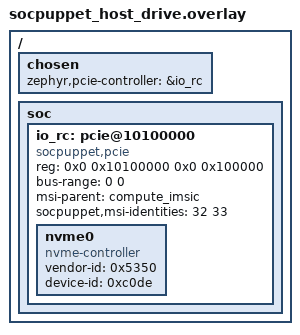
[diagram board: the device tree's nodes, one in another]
/ {
	chosen {
		zephyr,pcie-controller = &io_rc;
	};

	soc {
		io_rc: pcie@10100000 {
			compatible = "socpuppet,pcie";
			reg = <0x0 0x10100000 0x0 0x100000>;
			device_type = "pci";
			#address-cells = <3>;
			#size-cells = <2>;
			bus-range = <0 0>;
			ranges = <0x2000000 0x0 0x10800000 0x0 0x10800000 0x0 0x100000>;
		};
	};
};

&io_rc {
	msi-parent = <&compute_imsic>;
	socpuppet,msi-identities = <32 33>;

	nvme0: nvme0 {
		compatible = "nvme-controller";
		vendor-id = <0x5350>;
		device-id = <0xc0de>;
	};
};
